VERSION ""
NS_ :

BS_:

BU_: DCM FSM JCT DEBUG

BO_ 200 DCM_Vitals: 1 DCM
SG_ DCM_Heartbeat : 0|1@1+ (1,0) [0|1] "" DEBUG

BO_ 201 DCM_CanFifoOverflow: 8 DCM
SG_ DCM_TxOverflowCount : 0|32@1+ (1,0) [0|4294967295] "" DEBUG
SG_ DCM_RxOverflowCount : 32|32@1+ (1,0) [0|4294967295] "" DEBUG

BO_ 203 DCM_WatchdogTimeout: 4 DCM
SG_ DCM_Task : 0|32@1+ (1,0) [0|4294967295] "" DEBUG

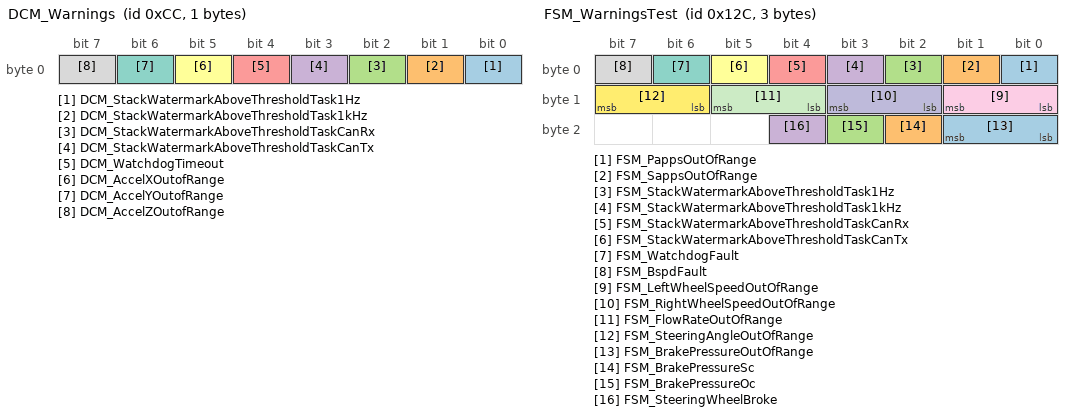
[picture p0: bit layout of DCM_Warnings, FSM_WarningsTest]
BO_ 204 DCM_Warnings: 1 DCM
SG_ DCM_StackWatermarkAboveThresholdTask1Hz : 0|1@1+ (1,0) [0|1] "" DEBUG
SG_ DCM_StackWatermarkAboveThresholdTask1kHz : 1|1@1+ (1,0) [0|1] "" DEBUG
SG_ DCM_StackWatermarkAboveThresholdTaskCanRx : 2|1@1+ (1,0) [0|1] "" DEBUG
SG_ DCM_StackWatermarkAboveThresholdTaskCanTx : 3|1@1+ (1,0) [0|1] "" DEBUG
SG_ DCM_WatchdogTimeout : 4|1@1+ (1,0) [0|1] "" DEBUG
SG_ DCM_AccelXOutofRange : 5|1@1+ (1,0) [0|1] "" DEBUG
SG_ DCM_AccelYOutofRange : 6|1@1+ (1,0) [0|1] "" DEBUG
SG_ DCM_AccelZOutofRange : 7|1@1+ (1,0) [0|1] "" DEBUG

BO_ 205 DCM_StateMachine: 1 DCM
SG_ DCM_State : 0|8@1+ (1,0) [0|255] "" DEBUG

BO_ 207 DCM_AirShutdownErrors: 1 DCM
SG_ DCM_MissingHeartbeat : 0|1@1+ (1,0) [0|1] "" DEBUG

BO_ 212 DCM_InverterSwitches: 1 DCM
SG_ DCM_RightInverterSwitch : 0|1@1+ (1,0) [0|1] "" DEBUG
SG_ DCM_LeftInverterSwitch : 1|1@1+ (1,0) [0|1] "" DEBUG

BO_ 13 FSM_PedalPosition: 4 FSM
SG_ FSM_MappedPedalPercentage : 0|32@1+ (2.3283064370807974e-08,0) [0|100] "%" DEBUG

BO_ 90 FSM_TorqueLimiting: 4 FSM
SG_ FSM_TorqueLimit : 0|32@1+ (3.492459655621196e-08,0) [0|150] "nM" DEBUG

BO_ 151 FSM_Apps: 8 FSM
SG_ FSM_PappsMappedPedalPercentage : 0|32@1+ (2.3283064370807974e-08,0) [0|100] "%" DEBUG,JCT
SG_ FSM_SappsMappedPedalPercentage : 32|32@1+ (2.3283064370807974e-08,0) [0|100] "%" DEBUG,JCT

BO_ 300 FSM_WarningsTest: 3 FSM
SG_ FSM_PappsOutOfRange : 0|1@1+ (1,0) [0|1] "" DEBUG
SG_ FSM_SappsOutOfRange : 1|1@1+ (1,0) [0|1] "" DEBUG
SG_ FSM_StackWatermarkAboveThresholdTask1Hz : 2|1@1+ (1,0) [0|1] "" DEBUG
SG_ FSM_StackWatermarkAboveThresholdTask1kHz : 3|1@1+ (1,0) [0|1] "" DEBUG
SG_ FSM_StackWatermarkAboveThresholdTaskCanRx : 4|1@1+ (1,0) [0|1] "" DEBUG
SG_ FSM_StackWatermarkAboveThresholdTaskCanTx : 5|1@1+ (1,0) [0|1] "" DEBUG
SG_ FSM_WatchdogFault : 6|1@1+ (1,0) [0|1] "" DEBUG
SG_ FSM_BspdFault : 7|1@1+ (1,0) [0|1] "" DEBUG
SG_ FSM_LeftWheelSpeedOutOfRange : 8|2@1+ (1,0) [0|3] "" DEBUG
SG_ FSM_RightWheelSpeedOutOfRange : 10|2@1+ (1,0) [0|3] "" DEBUG
SG_ FSM_FlowRateOutOfRange : 12|2@1+ (1,0) [0|3] "" DEBUG
SG_ FSM_SteeringAngleOutOfRange : 14|2@1+ (1,0) [0|3] "" DEBUG
SG_ FSM_BrakePressureOutOfRange : 16|2@1+ (1,0) [0|3] "" DEBUG
SG_ FSM_BrakePressureSc : 18|1@1+ (1,0) [0|1] "" DEBUG
SG_ FSM_BrakePressureOc : 19|1@1+ (1,0) [0|1] "" DEBUG
SG_ FSM_SteeringWheelBroke : 20|1@1+ (1,0) [0|1] "" DEBUG

BO_ 301 FSM_Vitals: 1 FSM
SG_ FSM_Heartbeat : 0|1@1+ (1,0) [0|1] "" DEBUG

BO_ 302 FSM_CanFifoOverflow: 8 FSM
SG_ FSM_TxOverflowCount : 0|32@1+ (1,0) [0|4294967295] "" DEBUG
SG_ FSM_RxOverflowCount : 32|32@1+ (1,0) [0|4294967295] "" DEBUG

BO_ 304 FSM_WatchdogTimeout: 1 FSM
SG_ FSM_TaskName : 0|8@1+ (1,0) [0|255] "" DEBUG

BO_ 305 FSM_StateMachine: 1 FSM
SG_ FSM_State : 0|8@1+ (1,0) [0|255] "" DEBUG

BO_ 307 FSM_FlowMeter: 1 FSM
SG_ FSM_FlowRate : 0|8@1+ (0.39215686274509803,0) [0|100] "L/min" DEBUG

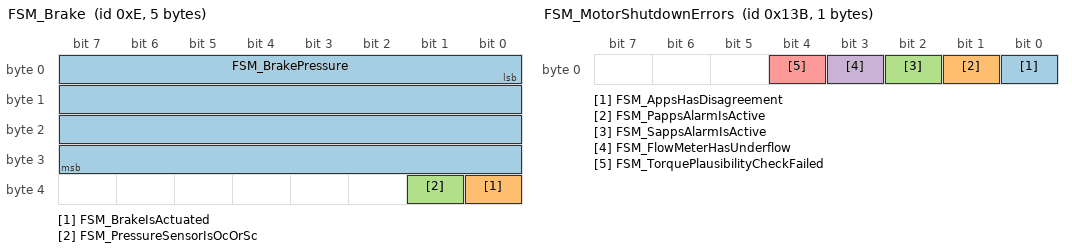
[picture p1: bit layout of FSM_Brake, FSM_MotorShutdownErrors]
BO_ 14 FSM_Brake: 5 FSM
SG_ FSM_BrakePressure : 0|32@1+ (5.820766092701993e-07,0) [0|2500] "psi" DEBUG
SG_ FSM_BrakeIsActuated : 32|1@1+ (1,0) [0|1] "" DEBUG
SG_ FSM_PressureSensorIsOcOrSc : 33|1@1+ (1,0) [0|1] "" DEBUG

BO_ 310 FSM_AirShutdownErrors: 1 FSM
SG_ FSM_MissingHeartbeat : 0|1@1+ (1,0) [0|1] "" DEBUG

BO_ 315 FSM_MotorShutdownErrors: 1 FSM
SG_ FSM_AppsHasDisagreement : 0|1@1+ (1,0) [0|1] "" DEBUG
SG_ FSM_PappsAlarmIsActive : 1|1@1+ (1,0) [0|1] "" DEBUG
SG_ FSM_SappsAlarmIsActive : 2|1@1+ (1,0) [0|1] "" DEBUG
SG_ FSM_FlowMeterHasUnderflow : 3|1@1+ (1,0) [0|1] "" DEBUG
SG_ FSM_TorquePlausibilityCheckFailed : 4|1@1+ (1,0) [0|1] "" DEBUG

BO_ 317 FSM_WheelSpeedSensors: 6 FSM
SG_ FSM_LeftWheelSpeed : 0|16@1+ (0.0022888532845044634,0) [0|150] "km/h" DEBUG
SG_ FSM_RightWheelSpeed : 32|16@1+ (0.0022888532845044634,0) [0|150] "km/h" DEBUG

BO_ 318 FSM_SteeringAngleSensor: 4 FSM
SG_ FSM_SteeringAngle : 0|32@1+ (5.122274161577754e-08,-110) [-110|110] "km/h" DEBUG

BO_ 41 FSM_Warnings: 1 FSM
SG_ FSM_TEST1 : 0|1@1+ (1,0) [0|1] "" DEBUG,DCM,JCT,JCT
SG_ FSM_TEST2 : 1|1@1+ (1,0) [0|1] "" DEBUG,DCM,JCT,JCT

BO_ 42 FSM_Faults: 1 FSM
SG_ FSM_FAULT_TEST3 : 0|1@1+ (1,0) [0|1] "" DEBUG,DCM,JCT

BO_ 601 JCT_Vitals: 5 JCT
SG_ JCT_Heartbeat : 0|1@1+ (1.0,0) [0|1] "" DEBUG
SG_ JCT_Timestamp : 1|32@1+ (1,0) [0|4294967295] "" DEBUG

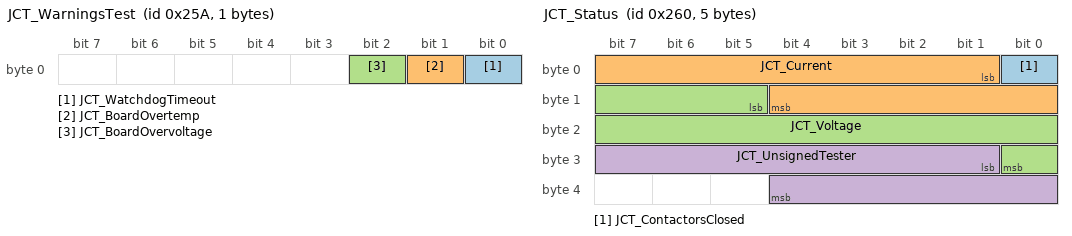
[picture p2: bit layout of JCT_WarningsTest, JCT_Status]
BO_ 602 JCT_WarningsTest: 1 JCT
SG_ JCT_WatchdogTimeout : 0|1@1+ (1,0) [0|1] "" DEBUG
SG_ JCT_BoardOvertemp : 1|1@1+ (1,0) [0|1] "" DEBUG
SG_ JCT_BoardOvervoltage : 2|1@1+ (1,0) [0|1] "" DEBUG

BO_ 603 JCT_AirShutdownErrors: 1 JCT
SG_ JCT_DummyAirShutdown : 0|1@1+ (1,0) [0|1] "" DEBUG

BO_ 604 JCT_MotorShutdownErrors: 1 JCT
SG_ JCT_DummyMotorShutdown : 0|1@1+ (1,0) [0|1] "" DEBUG

BO_ 608 JCT_Status: 5 JCT
SG_ JCT_ContactorsClosed : 0|1@1+ (1,0) [0|1] "" DEBUG
SG_ JCT_Current : 1|12@1+ (0.02442002442002442,0) [0|100] "A" DEBUG
SG_ JCT_Voltage : 13|12@1+ (0.1221001221001221,0) [0|500] "V" DEBUG
SG_ JCT_UnsignedTester : 25|12@1- (1,0) [-2047|2046] "V" DEBUG

BO_ 51 JCT_Warnings: 1 JCT
SG_ JCT_TEST : 0|1@1+ (1,0) [0|1] "" DEBUG,DCM,FSM

BO_ 52 JCT_Faults: 0 JCT

BA_DEF_  "BusType" STRING ;
BA_DEF_DEF_  "BusType" "CAN";

BA_ "GenSigStartValue" SG_ 200 DCM_Heartbeat 0;
BA_ "GenSigStartValue" SG_ 201 DCM_TxOverflowCount 0;
BA_ "GenSigStartValue" SG_ 201 DCM_RxOverflowCount 0;
BA_ "GenSigStartValue" SG_ 203 DCM_Task 0;
BA_ "GenSigStartValue" SG_ 204 DCM_StackWatermarkAboveThresholdTask1Hz 0;
BA_ "GenSigStartValue" SG_ 204 DCM_StackWatermarkAboveThresholdTask1kHz 0;
BA_ "GenSigStartValue" SG_ 204 DCM_StackWatermarkAboveThresholdTaskCanRx 0;
BA_ "GenSigStartValue" SG_ 204 DCM_StackWatermarkAboveThresholdTaskCanTx 0;
BA_ "GenSigStartValue" SG_ 204 DCM_WatchdogTimeout 0;
BA_ "GenSigStartValue" SG_ 204 DCM_AccelXOutofRange 0;
BA_ "GenSigStartValue" SG_ 204 DCM_AccelYOutofRange 0;
BA_ "GenSigStartValue" SG_ 204 DCM_AccelZOutofRange 0;
BA_ "GenSigStartValue" SG_ 205 DCM_State 0;
BA_ "GenSigStartValue" SG_ 207 DCM_MissingHeartbeat 0;
BA_ "GenSigStartValue" SG_ 212 DCM_RightInverterSwitch 0;
BA_ "GenSigStartValue" SG_ 212 DCM_LeftInverterSwitch 0;
BA_ "GenSigStartValue" SG_ 13 FSM_MappedPedalPercentage 0;
BA_ "GenSigStartValue" SG_ 90 FSM_TorqueLimit 0;
BA_ "GenSigStartValue" SG_ 151 FSM_PappsMappedPedalPercentage 0;
BA_ "GenSigStartValue" SG_ 151 FSM_SappsMappedPedalPercentage 0;
BA_ "GenSigStartValue" SG_ 300 FSM_PappsOutOfRange 0;
BA_ "GenSigStartValue" SG_ 300 FSM_SappsOutOfRange 0;
BA_ "GenSigStartValue" SG_ 300 FSM_StackWatermarkAboveThresholdTask1Hz 0;
BA_ "GenSigStartValue" SG_ 300 FSM_StackWatermarkAboveThresholdTask1kHz 0;
BA_ "GenSigStartValue" SG_ 300 FSM_StackWatermarkAboveThresholdTaskCanRx 0;
BA_ "GenSigStartValue" SG_ 300 FSM_StackWatermarkAboveThresholdTaskCanTx 0;
BA_ "GenSigStartValue" SG_ 300 FSM_WatchdogFault 0;
BA_ "GenSigStartValue" SG_ 300 FSM_BspdFault 0;
BA_ "GenSigStartValue" SG_ 300 FSM_LeftWheelSpeedOutOfRange 0;
BA_ "GenSigStartValue" SG_ 300 FSM_RightWheelSpeedOutOfRange 0;
BA_ "GenSigStartValue" SG_ 300 FSM_FlowRateOutOfRange 0;
BA_ "GenSigStartValue" SG_ 300 FSM_SteeringAngleOutOfRange 0;
BA_ "GenSigStartValue" SG_ 300 FSM_BrakePressureOutOfRange 0;
BA_ "GenSigStartValue" SG_ 300 FSM_BrakePressureSc 0;
BA_ "GenSigStartValue" SG_ 300 FSM_BrakePressureOc 0;
BA_ "GenSigStartValue" SG_ 300 FSM_SteeringWheelBroke 0;
BA_ "GenSigStartValue" SG_ 301 FSM_Heartbeat 0;
BA_ "GenSigStartValue" SG_ 302 FSM_TxOverflowCount 0;
BA_ "GenSigStartValue" SG_ 302 FSM_RxOverflowCount 0;
BA_ "GenSigStartValue" SG_ 304 FSM_TaskName 0;
BA_ "GenSigStartValue" SG_ 305 FSM_State 0;
BA_ "GenSigStartValue" SG_ 307 FSM_FlowRate 0;
BA_ "GenSigStartValue" SG_ 14 FSM_BrakePressure 0;
BA_ "GenSigStartValue" SG_ 14 FSM_BrakeIsActuated 0;
BA_ "GenSigStartValue" SG_ 14 FSM_PressureSensorIsOcOrSc 0;
BA_ "GenSigStartValue" SG_ 310 FSM_MissingHeartbeat 0;
BA_ "GenSigStartValue" SG_ 315 FSM_AppsHasDisagreement 0;
BA_ "GenSigStartValue" SG_ 315 FSM_PappsAlarmIsActive 0;
BA_ "GenSigStartValue" SG_ 315 FSM_SappsAlarmIsActive 0;
BA_ "GenSigStartValue" SG_ 315 FSM_FlowMeterHasUnderflow 0;
BA_ "GenSigStartValue" SG_ 315 FSM_TorquePlausibilityCheckFailed 0;
BA_ "GenSigStartValue" SG_ 317 FSM_LeftWheelSpeed 0;
BA_ "GenSigStartValue" SG_ 317 FSM_RightWheelSpeed 0;
BA_ "GenSigStartValue" SG_ 318 FSM_SteeringAngle -110;
BA_ "GenSigStartValue" SG_ 41 FSM_TEST1 0;
BA_ "GenSigStartValue" SG_ 41 FSM_TEST2 0;
BA_ "GenSigStartValue" SG_ 42 FSM_FAULT_TEST3 0;
BA_ "GenSigStartValue" SG_ 601 JCT_Heartbeat 0;
BA_ "GenSigStartValue" SG_ 601 JCT_Timestamp 0;
BA_ "GenSigStartValue" SG_ 602 JCT_WatchdogTimeout 0;
BA_ "GenSigStartValue" SG_ 602 JCT_BoardOvertemp 0;
BA_ "GenSigStartValue" SG_ 602 JCT_BoardOvervoltage 0;
BA_ "GenSigStartValue" SG_ 603 JCT_DummyAirShutdown 0;
BA_ "GenSigStartValue" SG_ 604 JCT_DummyMotorShutdown 0;
BA_ "GenSigStartValue" SG_ 608 JCT_ContactorsClosed 0;
BA_ "GenSigStartValue" SG_ 608 JCT_Current 50;
BA_ "GenSigStartValue" SG_ 608 JCT_Voltage 0;
BA_ "GenSigStartValue" SG_ 608 JCT_UnsignedTester -2047;
BA_ "GenSigStartValue" SG_ 51 JCT_TEST 0;

BA_ "GenMsgCycleTime" BO_ 200  1000;
BA_ "GenMsgCycleTime" BO_ 201  1000;
BA_ "GenMsgCycleTime" BO_ 203  1000;
BA_ "GenMsgCycleTime" BO_ 204  1000;
BA_ "GenMsgCycleTime" BO_ 205  1000;
BA_ "GenMsgCycleTime" BO_ 207  1000;
BA_ "GenMsgCycleTime" BO_ 212  1000;
BA_ "GenMsgCycleTime" BO_ 13  1000;
BA_ "GenMsgCycleTime" BO_ 90  1000;
BA_ "GenMsgCycleTime" BO_ 151  1000;
BA_ "GenMsgCycleTime" BO_ 300  100;
BA_ "GenMsgCycleTime" BO_ 301  1000;
BA_ "GenMsgCycleTime" BO_ 302  1000;
BA_ "GenMsgCycleTime" BO_ 304  1000;
BA_ "GenMsgCycleTime" BO_ 305  1000;
BA_ "GenMsgCycleTime" BO_ 307  1000;
BA_ "GenMsgCycleTime" BO_ 14  1000;
BA_ "GenMsgCycleTime" BO_ 310  1000;
BA_ "GenMsgCycleTime" BO_ 315  1000;
BA_ "GenMsgCycleTime" BO_ 317  1000;
BA_ "GenMsgCycleTime" BO_ 318  1000;
BA_ "GenMsgCycleTime" BO_ 41  1000;
BA_ "GenMsgCycleTime" BO_ 42  100;
BA_ "GenMsgCycleTime" BO_ 601  1000;
BA_ "GenMsgCycleTime" BO_ 603  1000;
BA_ "GenMsgCycleTime" BO_ 604  100;
BA_ "GenMsgCycleTime" BO_ 608  100;
BA_ "GenMsgCycleTime" BO_ 51  1000;
BA_ "GenMsgCycleTime" BO_ 52  100;

VAL_ 200 DCM_Heartbeat 0 "FALSE" 1 "TRUE";
VAL_ 301 FSM_Heartbeat 0 "FALSE" 1 "TRUE";
VAL_ 608 JCT_ContactorsClosed 0 "AIR_OPEN" 1 "AIR_CLOSED";
